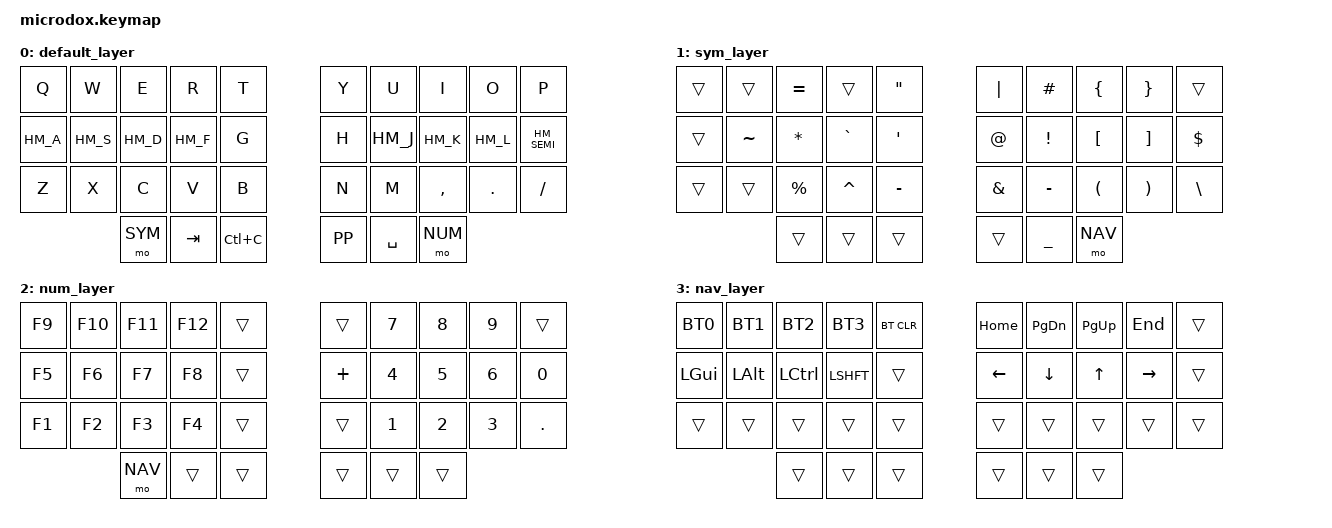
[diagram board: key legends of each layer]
/*
 * Copyright (c) 2020 The ZMK Contributors
 *
 * SPDX-License-Identifier: MIT
 */

#include <behaviors.dtsi>
#include <dt-bindings/zmk/keys.h>
#include <dt-bindings/zmk/bt.h>
#include "combos.dtsi"
#include "homerow.dtsi"
/* #include "accented_letters.dtsi" */
/* #include "tapdances.dtsi" */
#include "definitions.dtsi"
#include "microdox_right.overlay"

/ {
        keymap {
                compatible = "zmk,keymap";

                default_layer {
                        bindings = <
   &kp Q &kp W &kp E &kp R &kp T   &kp Y &kp U  &kp I     &kp O   &kp P
   HM_A  HM_S  HM_D  HM_F  &kp G   &kp H HM_J   HM_K      HM_L    HM_SEMI 
   &kp Z &kp X &kp C &kp V &kp B   &kp N &kp M  &kp COMMA &kp DOT &kp FSLH
          &mo SYM &kp TAB &kp LC(C)&kp K_PP &kp SPACE &mo NUM 
                        >;
                };

                sym_layer {
                        bindings = <
   &trans       &trans     &kp EQUAL &trans    &kp DQT    &kp PIPE &kp HASH  &kp LBRC &kp RBRC  &trans
   &trans       &kp TILDE  &kp STAR  &kp GRAVE &kp SQT    &kp AT   &kp EXCL  &kp LBKT &kp RBKT  &kp DLLR
   &trans       &trans     &kp PRCNT &kp CARET &kp MINUS  &kp AMPS &kp MINUS &kp LPAR &kp RPAR  &kp BSLH
                           &trans    &trans    &trans     &trans   &kp UNDER &mo NAV
                        >;
                };

                num_layer {
                        bindings = <
   &kp F9    &kp F10   &kp F11   &kp F12   &trans      &trans    &kp N7    &kp N8     &kp N9   &trans  
   &kp F5    &kp F6    &kp F7    &kp F8    &trans      &kp PLUS  &kp N4    &kp N5     &kp N6   &kp N0  
   &kp F1    &kp F2    &kp F3    &kp F4    &trans      &trans    &kp N1    &kp N2     &kp N3   &kp DOT 
                       &mo NAV   &trans    &trans      &trans    &trans    &trans  
                        >;
                };

/*                 accents_layer { */
/*                         bindings = < */
/*    &trans    &trans    &e_acute  &e_grave  &trans      &ded_uml  &u_grave  &i_circu   &o_circu &trans */
/*    &a_grave  &a_circu  &e_circu  &trans    &trans      &ded_cir  &trans    &trans     &trans   &trans */   
/*    &trans    &trans    &c_cdila  &trans    &trans      &trans    &trans    &trans     &trans   &trans */   
/*                        &trans    &trans    &trans      &trans    &trans    &trans */   
/*                         >; */
/*                 }; */

                nav_layer {
                        bindings = <
   BT0        BT1        BT2        BT3       &bt BT_CLR  &kp HOME  &kp PG_DN &kp PG_UP &kp END   &trans   
   &kp LGUI   &kp LALT   &kp LCTRL  &LSHFT    &trans      &kp LEFT  &kp DOWN  &kp UP    &kp RIGHT &trans  
   &trans     &trans     &trans     &trans    &trans      &trans    &trans    &trans    &trans    &trans  
                         &trans     &trans    &trans      &trans    &trans    &trans  
                        >;

                     sensor-bindings = <&inc_dec_kp C_VOL_UP C_VOL_DN>;

                };

        };
};
